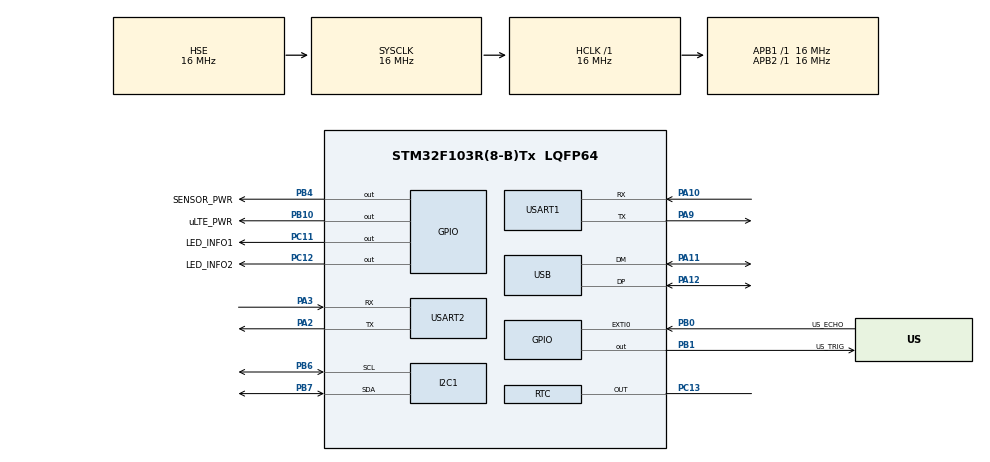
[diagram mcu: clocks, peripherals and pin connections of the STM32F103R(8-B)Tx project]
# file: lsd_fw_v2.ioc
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Mcu.Family=STM32F1
Mcu.Name=STM32F103R(8-B)Tx
Mcu.Package=LQFP64
NVIC.EXTI0_IRQn=true\:0\:0\:false\:false\:true\:true\:true\:true
NVIC.PVD_IRQn=true\:0\:0\:false\:false\:true\:true\:true\:true
NVIC.PriorityGroup=NVIC_PRIORITYGROUP_4
NVIC.RTC_Alarm_IRQn=true\:0\:0\:false\:false\:true\:true\:true\:true
NVIC.RTC_IRQn=true\:0\:0\:false\:false\:true\:true\:true\:true
NVIC.TIM2_IRQn=true\:0\:0\:false\:false\:true\:true\:true\:true
NVIC.TIM3_IRQn=true\:0\:0\:false\:false\:true\:true\:true\:true
NVIC.TIM4_IRQn=true\:0\:0\:false\:false\:true\:true\:true\:true
NVIC.USART2_IRQn=true\:0\:0\:false\:false\:true\:true\:true\:true
NVIC.USB_HP_CAN1_TX_IRQn=true\:0\:0\:false\:false\:true\:true\:true\:true
NVIC.USB_LP_CAN1_RX0_IRQn=true\:0\:0\:false\:false\:true\:false\:true\:true
PA10.Mode=Asynchronous
PA10.Signal=USART1_RX
PA11.Mode=Device
PA11.Signal=USB_DM
PA12.Mode=Device
PA12.Signal=USB_DP
PA13.Mode=Serial_Wire
PA13.Signal=SYS_JTMS-SWDIO
PA14.Mode=Serial_Wire
PA14.Signal=SYS_JTCK-SWCLK
PA2.Mode=Asynchronous
PA2.Signal=USART2_TX
PA3.Mode=Asynchronous
PA3.Signal=USART2_RX
PA9.Mode=Asynchronous
PA9.Signal=USART1_TX
PB0.GPIO_Label=US_ECHO
PB0.GPIO_ModeDefaultEXTI=GPIO_MODE_IT_RISING_FALLING
PB0.Signal=GPXTI0
PB1.GPIO_Label=US_TRIG
PB1.Signal=GPIO_Output
PB10.GPIO_Label=uLTE_PWR
PB10.GPIO_PuPd=GPIO_PULLUP
PB10.PinState=GPIO_PIN_SET
PB10.Signal=GPIO_Output
PB4.GPIO_Label=SENSOR_PWR
PB4.PinState=GPIO_PIN_RESET
PB4.Signal=GPIO_Output
PB6.Mode=I2C
PB6.Signal=I2C1_SCL
PB7.Mode=I2C
PB7.Signal=I2C1_SDA
PC11.GPIO_Label=LED_INFO1
PC11.GPIO_PuPd=GPIO_NOPULL
PC11.PinState=GPIO_PIN_RESET
PC11.Signal=GPIO_Output
PC12.GPIO_Label=LED_INFO2
PC12.GPIO_PuPd=GPIO_NOPULL
PC12.PinState=GPIO_PIN_RESET
PC12.Signal=GPIO_Output
PC13-TAMPER-RTC.Mode=RTC OUT
PC13-TAMPER-RTC.Signal=RTC_OUT
PD0-OSC_IN.Mode=HSE-External-Oscillator
PD0-OSC_IN.Signal=RCC_OSC_IN
PD1-OSC_OUT.Mode=HSE-External-Oscillator
PD1-OSC_OUT.Signal=RCC_OSC_OUT
ProjectManager.HeapSize=0x200
ProjectManager.StackSize=0x400
ProjectManager.TargetToolchain=STM32CubeIDE
RCC.AHBFreq_Value=16000000
RCC.APB1Freq_Value=16000000
RCC.APB1TimFreq_Value=16000000
RCC.APB2Freq_Value=16000000
RCC.APB2TimFreq_Value=16000000
RCC.HCLKFreq_Value=16000000
RCC.HSE_VALUE=16000000
RCC.PLLMUL=RCC_PLL_MUL3
RCC.PLLSourceVirtual=RCC_PLLSOURCE_HSE
RCC.SYSCLKFreq_VALUE=16000000
RCC.SYSCLKSource=RCC_SYSCLKSOURCE_HSE
RCC.USBFreq_Value=48000000
RTC.Format=RTC_FORMAT_BIN
RTC.Minutes_A-RTC\ OUT=0
RTC.Seconds_A-RTC\ OUT=10
TIM2.Channel-Output\ Compare1\ No\ Output=TIM_CHANNEL_1
TIM2.Channel-Output\ Compare2\ No\ Output=TIM_CHANNEL_2
TIM2.Prescaler=16000 - 1
TIM3.Prescaler=16 - 1
TIM4.Prescaler=16 - 1
USART1.VirtualMode=VM_ASYNC
USART2.VirtualMode=VM_ASYNC
USB_DEVICE.CLASS_NAME_FS=CDC
USB_DEVICE.VirtualMode=Cdc
USB_DEVICE.VirtualModeFS=Cdc_FS
VP_RTC_VS_RTC_Activate.Mode=RTC_Enabled
VP_RTC_VS_RTC_Calendar.Mode=RTC_Calendar
VP_TIM2_VS_ClockSourceINT.Mode=Internal
VP_TIM2_VS_no_output1.Mode=Output Compare1 No Output
VP_TIM2_VS_no_output2.Mode=Output Compare2 No Output
VP_TIM3_VS_ClockSourceINT.Mode=Internal
VP_TIM4_VS_ClockSourceINT.Mode=Internal
VP_USB_DEVICE_VS_USB_DEVICE_CDC_FS.Mode=CDC_FS
board=custom

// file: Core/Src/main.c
/* USER CODE BEGIN Header */
/**
  ******************************************************************************
  * @file           : main.c
  * @brief          : Main program body
  ******************************************************************************
  * @attention
  *
  * Copyright (c) 2024 STMicroelectronics.
  * All rights reserved.
  *
  * This software is licensed under terms that can be found in the LICENSE file
  * in the root directory of this software component.
  * If no LICENSE file comes with this software, it is provided AS-IS.
  *
  ******************************************************************************
  */
/* USER CODE END Header */
#include "main.h"
#include "usb_device.h"

/* USER CODE BEGIN Includes */
#include "MyDriversInc/lsd_config.h"
#include "MyDriversInc/global_var.h"
#include "usbd_cdc_if.h"
//#include "MyDriversInc/leds.h"
//#include "MyDriversInc/aht20.h"
//#include "MyDriversInc/ajsr04m.h"
//#include "MyDriversInc/le910r1br.h"
#include "MyServicesInc/state_machine.h"
/* USER CODE END Includes */

I2C_HandleTypeDef hi2c1;

RTC_HandleTypeDef hrtc;

TIM_HandleTypeDef htim2;
TIM_HandleTypeDef htim3;
TIM_HandleTypeDef htim4;

UART_HandleTypeDef huart1;
UART_HandleTypeDef huart2;

/* USER CODE BEGIN PV */
static LSD_MCU_PERIPH_HANDLES_T hmcu_peripherals;
/* USER CODE END PV */

void SystemClock_Config(void);
static void MX_GPIO_Init(void);
static void MX_TIM2_Init(void);
static void MX_TIM3_Init(void);
static void MX_I2C1_Init(void);
static void MX_TIM4_Init(void);
static void MX_USART1_UART_Init(void);
static void MX_RTC_Init(void);
static void MX_USART2_UART_Init(void);

int main(void)
{

  /* MCU Configuration--------------------------------------------------------*/

  /* Reset of all peripherals, Initializes the Flash interface and the Systick. */
  HAL_Init();

  /* Configure the system clock */
  SystemClock_Config();

  /* Initialize all configured peripherals */
  MX_GPIO_Init();
  MX_TIM2_Init();
  MX_TIM3_Init();
  MX_I2C1_Init();
  MX_TIM4_Init();
  MX_USART1_UART_Init();
  MX_RTC_Init();
  MX_USB_DEVICE_Init();
  MX_USART2_UART_Init();
  /* USER CODE BEGIN 2 */

  hmcu_peripherals.mcu_hi2c = &hi2c1;
  hmcu_peripherals.mcu_htim[LSD_TIM_GENERAL] = &htim2;
  hmcu_peripherals.mcu_htim[LSD_TIM_COMMON] = &htim3;
  hmcu_peripherals.mcu_htim[LSD_TIM_SENSORS] = &htim4;
  hmcu_peripherals.mcu_huart[LSD_UART_MODEM] = &huart1;
  hmcu_peripherals.mcu_huart[LSD_UART_FTDI] = &huart2;
  hmcu_peripherals.mcu_hrtc = &hrtc;

  state_machine_init( &hmcu_peripherals, &SystemClock_Config );

//	HAL_Delay( 2000 );
//	leds_turn_on( LSD_LED_BLUE );
//	le910r1br_power_on();
//	leds_turn_off( LSD_LED_BLUE );
//	HAL_Delay( 11000 );

  /* USER CODE END 2 */

  /* Infinite loop */
  while (1)
  {

    /* USER CODE BEGIN 3 */
	state_machine_run();

//	HAL_UART_Transmit( &huart1, modem_tx, 5, 1000 );
//	HAL_UART_Receive( &huart1, modem_rx, 64, 1000 );
//
//	CDC_Transmit_FS( modem_rx, strlen( (char *) modem_rx ) );
////	ret = ajsr04m_read_tof_blocking( 10000 );
//	HAL_Delay( 1000 );
  }
  /* USER CODE END 3 */
}

void SystemClock_Config(void)
{
  RCC_OscInitTypeDef RCC_OscInitStruct = {0};
  RCC_ClkInitTypeDef RCC_ClkInitStruct = {0};
  RCC_PeriphCLKInitTypeDef PeriphClkInit = {0};

  /** Initializes the RCC Oscillators according to the specified parameters
  * in the RCC_OscInitTypeDef structure.
  */
  RCC_OscInitStruct.OscillatorType = RCC_OSCILLATORTYPE_LSI|RCC_OSCILLATORTYPE_HSE;
  RCC_OscInitStruct.HSEState = RCC_HSE_ON;
  RCC_OscInitStruct.HSEPredivValue = RCC_HSE_PREDIV_DIV1;
  RCC_OscInitStruct.HSIState = RCC_HSI_ON;
  RCC_OscInitStruct.LSIState = RCC_LSI_ON;
  RCC_OscInitStruct.PLL.PLLState = RCC_PLL_ON;
  RCC_OscInitStruct.PLL.PLLSource = RCC_PLLSOURCE_HSE;
  RCC_OscInitStruct.PLL.PLLMUL = RCC_PLL_MUL3;
  if (HAL_RCC_OscConfig(&RCC_OscInitStruct) != HAL_OK)
  {
    Error_Handler();
  }

  /** Initializes the CPU, AHB and APB buses clocks
  */
  RCC_ClkInitStruct.ClockType = RCC_CLOCKTYPE_HCLK|RCC_CLOCKTYPE_SYSCLK
                              |RCC_CLOCKTYPE_PCLK1|RCC_CLOCKTYPE_PCLK2;
  RCC_ClkInitStruct.SYSCLKSource = RCC_SYSCLKSOURCE_HSE;
  RCC_ClkInitStruct.AHBCLKDivider = RCC_SYSCLK_DIV1;
  RCC_ClkInitStruct.APB1CLKDivider = RCC_HCLK_DIV1;
  RCC_ClkInitStruct.APB2CLKDivider = RCC_HCLK_DIV1;

  if (HAL_RCC_ClockConfig(&RCC_ClkInitStruct, FLASH_LATENCY_0) != HAL_OK)
  {
    Error_Handler();
  }
  PeriphClkInit.PeriphClockSelection = RCC_PERIPHCLK_RTC|RCC_PERIPHCLK_USB;
  PeriphClkInit.RTCClockSelection = RCC_RTCCLKSOURCE_LSI;
  PeriphClkInit.UsbClockSelection = RCC_USBCLKSOURCE_PLL;
  if (HAL_RCCEx_PeriphCLKConfig(&PeriphClkInit) != HAL_OK)
  {
    Error_Handler();
  }
}

static void MX_I2C1_Init(void)
{

  hi2c1.Instance = I2C1;
  hi2c1.Init.ClockSpeed = 100000;
  hi2c1.Init.DutyCycle = I2C_DUTYCYCLE_2;
  hi2c1.Init.OwnAddress1 = 0;
  hi2c1.Init.AddressingMode = I2C_ADDRESSINGMODE_7BIT;
  hi2c1.Init.DualAddressMode = I2C_DUALADDRESS_DISABLE;
  hi2c1.Init.OwnAddress2 = 0;
  hi2c1.Init.GeneralCallMode = I2C_GENERALCALL_DISABLE;
  hi2c1.Init.NoStretchMode = I2C_NOSTRETCH_DISABLE;
  if (HAL_I2C_Init(&hi2c1) != HAL_OK)
  {
    Error_Handler();
  }

}

static void MX_RTC_Init(void)
{

  RTC_TimeTypeDef sTime = {0};
  RTC_DateTypeDef DateToUpdate = {0};
  RTC_AlarmTypeDef sAlarm = {0};

  /** Initialize RTC Only
  */
  hrtc.Instance = RTC;
  hrtc.Init.AsynchPrediv = RTC_AUTO_1_SECOND;
  hrtc.Init.OutPut = RTC_OUTPUTSOURCE_ALARM;
  if (HAL_RTC_Init(&hrtc) != HAL_OK)
  {
    Error_Handler();
  }

  /** Initialize RTC and set the Time and Date
  */
  sTime.Hours = 0;
  sTime.Minutes = 0;
  sTime.Seconds = 0;

  if (HAL_RTC_SetTime(&hrtc, &sTime, RTC_FORMAT_BIN) != HAL_OK)
  {
    Error_Handler();
  }
  DateToUpdate.WeekDay = RTC_WEEKDAY_MONDAY;
  DateToUpdate.Month = RTC_MONTH_JANUARY;
  DateToUpdate.Date = 1;
  DateToUpdate.Year = 0;

  if (HAL_RTC_SetDate(&hrtc, &DateToUpdate, RTC_FORMAT_BIN) != HAL_OK)
  {
    Error_Handler();
  }

  /** Enable the Alarm A
  */
  sAlarm.AlarmTime.Hours = 0;
  sAlarm.AlarmTime.Minutes = 0;
  sAlarm.AlarmTime.Seconds = 10;
  sAlarm.Alarm = RTC_ALARM_A;
  if (HAL_RTC_SetAlarm_IT(&hrtc, &sAlarm, RTC_FORMAT_BIN) != HAL_OK)
  {
    Error_Handler();
  }

}

static void MX_TIM2_Init(void)
{

  TIM_ClockConfigTypeDef sClockSourceConfig = {0};
  TIM_MasterConfigTypeDef sMasterConfig = {0};
  TIM_OC_InitTypeDef sConfigOC = {0};

  htim2.Instance = TIM2;
  htim2.Init.Prescaler = 16000 - 1;
  htim2.Init.CounterMode = TIM_COUNTERMODE_UP;
  htim2.Init.Period = 65535;
  htim2.Init.ClockDivision = TIM_CLOCKDIVISION_DIV1;
  htim2.Init.AutoReloadPreload = TIM_AUTORELOAD_PRELOAD_DISABLE;
  if (HAL_TIM_Base_Init(&htim2) != HAL_OK)
  {
    Error_Handler();
  }
  sClockSourceConfig.ClockSource = TIM_CLOCKSOURCE_INTERNAL;
  if (HAL_TIM_ConfigClockSource(&htim2, &sClockSourceConfig) != HAL_OK)
  {
    Error_Handler();
  }
  if (HAL_TIM_OC_Init(&htim2) != HAL_OK)
  {
    Error_Handler();
  }
  sMasterConfig.MasterOutputTrigger = TIM_TRGO_RESET;
  sMasterConfig.MasterSlaveMode = TIM_MASTERSLAVEMODE_DISABLE;
  if (HAL_TIMEx_MasterConfigSynchronization(&htim2, &sMasterConfig) != HAL_OK)
  {
    Error_Handler();
  }
  sConfigOC.OCMode = TIM_OCMODE_TIMING;
  sConfigOC.Pulse = 0;
  sConfigOC.OCPolarity = TIM_OCPOLARITY_HIGH;
  sConfigOC.OCFastMode = TIM_OCFAST_DISABLE;
  if (HAL_TIM_OC_ConfigChannel(&htim2, &sConfigOC, TIM_CHANNEL_1) != HAL_OK)
  {
    Error_Handler();
  }
  if (HAL_TIM_OC_ConfigChannel(&htim2, &sConfigOC, TIM_CHANNEL_2) != HAL_OK)
  {
    Error_Handler();
  }

}

static void MX_TIM3_Init(void)
{

  TIM_ClockConfigTypeDef sClockSourceConfig = {0};
  TIM_MasterConfigTypeDef sMasterConfig = {0};

  htim3.Instance = TIM3;
  htim3.Init.Prescaler = 16 - 1;
  htim3.Init.CounterMode = TIM_COUNTERMODE_UP;
  htim3.Init.Period = 65535;
  htim3.Init.ClockDivision = TIM_CLOCKDIVISION_DIV1;
  htim3.Init.AutoReloadPreload = TIM_AUTORELOAD_PRELOAD_DISABLE;
  if (HAL_TIM_Base_Init(&htim3) != HAL_OK)
  {
    Error_Handler();
  }
  sClockSourceConfig.ClockSource = TIM_CLOCKSOURCE_INTERNAL;
  if (HAL_TIM_ConfigClockSource(&htim3, &sClockSourceConfig) != HAL_OK)
  {
    Error_Handler();
  }
  sMasterConfig.MasterOutputTrigger = TIM_TRGO_RESET;
  sMasterConfig.MasterSlaveMode = TIM_MASTERSLAVEMODE_DISABLE;
  if (HAL_TIMEx_MasterConfigSynchronization(&htim3, &sMasterConfig) != HAL_OK)
  {
    Error_Handler();
  }

}

static void MX_TIM4_Init(void)
{

  TIM_ClockConfigTypeDef sClockSourceConfig = {0};
  TIM_MasterConfigTypeDef sMasterConfig = {0};

  htim4.Instance = TIM4;
  htim4.Init.Prescaler = 16 - 1;
  htim4.Init.CounterMode = TIM_COUNTERMODE_UP;
  htim4.Init.Period = 65535;
  htim4.Init.ClockDivision = TIM_CLOCKDIVISION_DIV1;
  htim4.Init.AutoReloadPreload = TIM_AUTORELOAD_PRELOAD_DISABLE;
  if (HAL_TIM_Base_Init(&htim4) != HAL_OK)
  {
    Error_Handler();
  }
  sClockSourceConfig.ClockSource = TIM_CLOCKSOURCE_INTERNAL;
  if (HAL_TIM_ConfigClockSource(&htim4, &sClockSourceConfig) != HAL_OK)
  {
    Error_Handler();
  }
  sMasterConfig.MasterOutputTrigger = TIM_TRGO_RESET;
  sMasterConfig.MasterSlaveMode = TIM_MASTERSLAVEMODE_DISABLE;
  if (HAL_TIMEx_MasterConfigSynchronization(&htim4, &sMasterConfig) != HAL_OK)
  {
    Error_Handler();
  }

}

static void MX_USART1_UART_Init(void)
{

  huart1.Instance = USART1;
  huart1.Init.BaudRate = 115200;
  huart1.Init.WordLength = UART_WORDLENGTH_8B;
  huart1.Init.StopBits = UART_STOPBITS_1;
  huart1.Init.Parity = UART_PARITY_NONE;
  huart1.Init.Mode = UART_MODE_TX_RX;
  huart1.Init.HwFlowCtl = UART_HWCONTROL_NONE;
  huart1.Init.OverSampling = UART_OVERSAMPLING_16;
  if (HAL_UART_Init(&huart1) != HAL_OK)
  {
    Error_Handler();
  }

}

static void MX_USART2_UART_Init(void)
{

  huart2.Instance = USART2;
  huart2.Init.BaudRate = 115200;
  huart2.Init.WordLength = UART_WORDLENGTH_8B;
  huart2.Init.StopBits = UART_STOPBITS_1;
  huart2.Init.Parity = UART_PARITY_NONE;
  huart2.Init.Mode = UART_MODE_TX_RX;
  huart2.Init.HwFlowCtl = UART_HWCONTROL_NONE;
  huart2.Init.OverSampling = UART_OVERSAMPLING_16;
  if (HAL_UART_Init(&huart2) != HAL_OK)
  {
    Error_Handler();
  }

}

static void MX_GPIO_Init(void)
{
  GPIO_InitTypeDef GPIO_InitStruct = {0};

  /* GPIO Ports Clock Enable */
  __HAL_RCC_GPIOC_CLK_ENABLE();
  __HAL_RCC_GPIOD_CLK_ENABLE();
  __HAL_RCC_GPIOA_CLK_ENABLE();
  __HAL_RCC_GPIOB_CLK_ENABLE();

  /*Configure GPIO pin Output Level */
  HAL_GPIO_WritePin(GPIOB, US_TRIG_Pin|SENSOR_PWR_Pin, GPIO_PIN_RESET);

  /*Configure GPIO pin Output Level */
  HAL_GPIO_WritePin(uLTE_PWR_GPIO_Port, uLTE_PWR_Pin, GPIO_PIN_SET);

  /*Configure GPIO pin Output Level */
  HAL_GPIO_WritePin(GPIOC, LED_INFO1_Pin|LED_INFO2_Pin, GPIO_PIN_RESET);

  /*Configure GPIO pin : US_ECHO_Pin */
  GPIO_InitStruct.Pin = US_ECHO_Pin;
  GPIO_InitStruct.Mode = GPIO_MODE_IT_RISING_FALLING;
  GPIO_InitStruct.Pull = GPIO_NOPULL;
  HAL_GPIO_Init(US_ECHO_GPIO_Port, &GPIO_InitStruct);

  /*Configure GPIO pins : US_TRIG_Pin SENSOR_PWR_Pin */
  GPIO_InitStruct.Pin = US_TRIG_Pin|SENSOR_PWR_Pin;
  GPIO_InitStruct.Mode = GPIO_MODE_OUTPUT_PP;
  GPIO_InitStruct.Pull = GPIO_NOPULL;
  GPIO_InitStruct.Speed = GPIO_SPEED_FREQ_LOW;
  HAL_GPIO_Init(GPIOB, &GPIO_InitStruct);

  /*Configure GPIO pin : uLTE_PWR_Pin */
  GPIO_InitStruct.Pin = uLTE_PWR_Pin;
  GPIO_InitStruct.Mode = GPIO_MODE_OUTPUT_PP;
  GPIO_InitStruct.Pull = GPIO_PULLUP;
  GPIO_InitStruct.Speed = GPIO_SPEED_FREQ_LOW;
  HAL_GPIO_Init(uLTE_PWR_GPIO_Port, &GPIO_InitStruct);

  /*Configure GPIO pins : LED_INFO1_Pin LED_INFO2_Pin */
  GPIO_InitStruct.Pin = LED_INFO1_Pin|LED_INFO2_Pin;
  GPIO_InitStruct.Mode = GPIO_MODE_OUTPUT_PP;
  GPIO_InitStruct.Pull = GPIO_NOPULL;
  GPIO_InitStruct.Speed = GPIO_SPEED_FREQ_LOW;
  HAL_GPIO_Init(GPIOC, &GPIO_InitStruct);

  /* EXTI interrupt init*/
  HAL_NVIC_SetPriority(EXTI0_IRQn, 0, 0);
  HAL_NVIC_EnableIRQ(EXTI0_IRQn);

}

void Error_Handler(void)
{
  __disable_irq();
  while (1)
  {
  }
}
